AUTOSAR XML (schema 4-0-3)
standard types defined: Boolean, UInt16, UInt32
package /AUTOSAR_Platform/DataConstrs
  range DC_Boolean: raw 0..1
  range DC_UInt16: raw 0..65535
package /PATAC/MSM/ComponentTypes
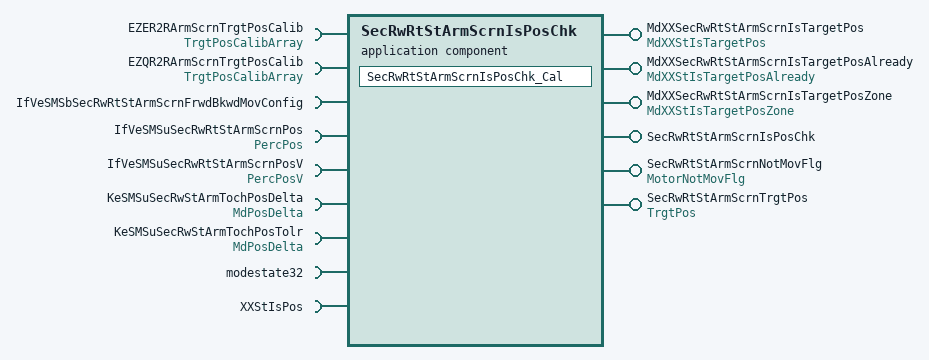
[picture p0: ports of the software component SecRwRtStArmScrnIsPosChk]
  application sw component type SecRwRtStArmScrnIsPosChk
    6 x provide port:
      MdXXSecRwRtStArmScrnIsTargetPos: nonqueued-sender-com-spec=data-element=MdXXStIsTargetPos/Val, provided-interface=MdXXStIsTargetPos
      MdXXSecRwRtStArmScrnIsTargetPosAlready: nonqueued-sender-com-spec=data-element=MdXXStIsTargetPosAlready/Val, provided-interface=MdXXStIsTargetPosAlready
      MdXXSecRwRtStArmScrnIsTargetPosZone: nonqueued-sender-com-spec=data-element=MdXXStIsTargetPosZone/Val, provided-interface=MdXXStIsTargetPosZone
      SecRwRtStArmScrnIsPosChk: server-com-spec{operation=Cal, queue-length=1}, provided-interface=SecRwRtStArmScrnIsPosChk
      SecRwRtStArmScrnNotMovFlg: nonqueued-sender-com-spec{data-element=MotorNotMovFlg/Val, init-value=0}, provided-interface=MotorNotMovFlg
      SecRwRtStArmScrnTrgtPos: nonqueued-sender-com-spec{data-element=TrgtPos/Val, init-value=4095}, provided-interface=TrgtPos
    9 x require port:
      EZER2RArmScrnTrgtPosCalib: nonqueued-receiver-com-spec{data-element=TrgtPosArray, filter=data-filter-type=ALWAYS, init-value=[4095, 4095, 4095]}, required-interface=TrgtPosCalibArray
      EZQR2RArmScrnTrgtPosCalib: nonqueued-receiver-com-spec{data-element=TrgtPosArray, filter=data-filter-type=ALWAYS, init-value=[4095, 4095, 4095]}, required-interface=TrgtPosCalibArray
      IfVeSMSbSecRwRtStArmScrnFrwdBkwdMovConfig: nonqueued-receiver-com-spec{data-element=IfVeSMSbSecRwRtStArmScrnFrwdBkwdMovConfig/Val, filter=data-filter-type=ALWAYS, init-value=0}, required-interface=IfVeSMSbSecRwRtStArmScrnFrwdBkwdMovConfig
      IfVeSMSuSecRwRtStArmScrnPos: nonqueued-receiver-com-spec{data-element=PercPos/Val, filter=data-filter-type=ALWAYS, init-value=0}, required-interface=PercPos
      IfVeSMSuSecRwRtStArmScrnPosV: nonqueued-receiver-com-spec{data-element=PercPosV/Val, filter=data-filter-type=ALWAYS, init-value=0}, required-interface=PercPosV
      KeSMSuSecRwStArmTochPosDelta: parameter-require-com-spec{init-value=150, parameter=Val}, required-interface=MdPosDelta
      KeSMSuSecRwStArmTochPosTolr: parameter-require-com-spec{init-value=150, parameter=Val}, required-interface=MdPosDelta
      modestate32: nonqueued-receiver-com-spec{data-element=modestate32/Val, filter=data-filter-type=ALWAYS, init-value=0}, required-interface=modestate32
      XXStIsPos: client-com-spec=Get, required-interface=XXStIsPos
    behavior SecRwRtStArmScrnIsPosChk_InternalBehavior
      operation invoked event OIT_SecRwRtStArmScrnIsPosChk_Cal_SecRwRtStArmScrnIsPosChk_Cal: start-on-event=SecRwRtStArmScrnIsPosChk_Cal, operation=SecRwRtStArmScrnIsPosChk.Cal
      runnable SecRwRtStArmScrnIsPosChk_Cal
        data-receive-point-by-arguments:
          6 x access:
            REC_EZER2RArmScrnTrgtPosCalib_TrgtPosArray: accessed-variable=EZER2RArmScrnTrgtPosCalib.TrgtPosArray
            REC_EZQR2RArmScrnTrgtPosCalib_TrgtPosArray: accessed-variable=EZQR2RArmScrnTrgtPosCalib.TrgtPosArray
            REC_IfVeSMSbSecRwRtStArmScrnFrwdBkwdMovConfig_Val: accessed-variable=IfVeSMSbSecRwRtStArmScrnFrwdBkwdMovConfig.Val
            REC_IfVeSMSuSecRwRtStArmScrnPos_Val: accessed-variable=IfVeSMSuSecRwRtStArmScrnPos.Val
            REC_IfVeSMSuSecRwRtStArmScrnPosV_Val: accessed-variable=IfVeSMSuSecRwRtStArmScrnPosV.Val
            REC_modestate32_Val: accessed-variable=modestate32.Val
        data-send-points:
          5 x access:
            SEND_MdXXSecRwRtStArmScrnIsTargetPos_Val: accessed-variable=MdXXSecRwRtStArmScrnIsTargetPos.Val
            SEND_MdXXSecRwRtStArmScrnIsTargetPosAlready_Val: accessed-variable=MdXXSecRwRtStArmScrnIsTargetPosAlready.Val
            SEND_MdXXSecRwRtStArmScrnIsTargetPosZone_Val: accessed-variable=MdXXSecRwRtStArmScrnIsTargetPosZone.Val
            SEND_SecRwRtStArmScrnNotMovFlg_Val: accessed-variable=SecRwRtStArmScrnNotMovFlg.Val
            SEND_SecRwRtStArmScrnTrgtPos_Val: accessed-variable=SecRwRtStArmScrnTrgtPos.Val
        parameter access PA_KeSMSuSecRwStArmTochPosDelta_Val: accessed-parameter=KeSMSuSecRwStArmTochPosDelta.Val
        parameter access PA_KeSMSuSecRwStArmTochPosTolr_Val: accessed-parameter=KeSMSuSecRwStArmTochPosTolr.Val
        sync call SC_XXStIsPos_Get: operation=XXStIsPos.Get, timeout=0
  swc implementation SecRwRtStArmScrnIsPosChk_Implementation: behavior=SecRwRtStArmScrnIsPosChk_InternalBehavior
    code-descriptors:
      code Default: artifact-descriptors=autosar-engineering-object={short-label=Default, category=SWSRC}
package /PATAC/MSM/ModeAdjust/CalPortInterface
  parameter interface MdPosDelta
    parameter data prototype Val: sw-calibration-access=READ-WRITE, type=UInt16
package /PATAC/MSM/ModeAdjust/DataType
  impl type TrgtPosCalibArray: category=ARRAY, sw-calibration-access=READ-ONLY, type-emitter=RTE  # 0:pos 1:max 2:min
    element Element: array-size=3, array-size-semantics=FIXED-SIZE, implementation-data-type=UInt16, invalid-value=0
package /PATAC/MSM/ModeAdjust/PortInterface
  client server interface SecRwRtStArmScrnIsPosChk
    operation Cal
  client server interface XXStIsPos
    operation Get
      8 x arg, all with server-argument-impl-policy=USE-ARGUMENT-TYPE:
        PosV: type=DataTypes/Boolean, direction=IN
        Pos: type=UInt16, direction=IN
        CalibArray: type=TrgtPosCalibArray, direction=IN
        Delta: type=UInt16, direction=IN
        Tolr: type=UInt16, direction=IN
        IsPos: type=DataTypes/Boolean, direction=OUT
        IsPosZone: type=DataTypes/Boolean, direction=OUT
        IsPosAlready: type=DataTypes/Boolean, direction=OUT
  9 x sender receiver interface:
    IfVeSMSbSecRwRtStArmScrnFrwdBkwdMovConfig: invalidation-policy{data-element=IfVeSMSbSecRwRtStArmScrnFrwdBkwdMovConfig/Val, handle-invalid=DONT-INVALIDATE}
      data Val: type=Implementation/Boolean
    MdXXStIsTargetPos: invalidation-policy{data-element=MdXXStIsTargetPos/Val, handle-invalid=DONT-INVALIDATE}
      data Val: type=UInt32
    MdXXStIsTargetPosAlready: invalidation-policy{data-element=MdXXStIsTargetPosAlready/Val, handle-invalid=DONT-INVALIDATE}
      data Val: type=UInt32
    MdXXStIsTargetPosZone: invalidation-policy{data-element=MdXXStIsTargetPosZone/Val, handle-invalid=DONT-INVALIDATE}
      data Val: type=UInt32
    modestate32: invalidation-policy{data-element=modestate32/Val, handle-invalid=DONT-INVALIDATE}
      data Val: type=UInt32
    MotorNotMovFlg: invalidation-policy{data-element=MotorNotMovFlg/Val, handle-invalid=DONT-INVALIDATE}
      data Val: type=Implementation/Boolean
    PercPos: invalidation-policy{data-element=PercPos/Val, handle-invalid=DONT-INVALIDATE}
      data Val: type=UInt16
    PercPosV: invalidation-policy{data-element=PercPosV/Val, handle-invalid=DONT-INVALIDATE}
      data Val: type=Implementation/Boolean
    TrgtPosCalibArray: invalidation-policy{data-element=TrgtPosArray, handle-invalid=DONT-INVALIDATE}
      data TrgtPosArray: type=TrgtPosCalibArray  # 0:Pos 1:Max 2:Min
package /PATAC/MSM/PortInterfaces
  sender receiver interface TrgtPos: invalidation-policy{data-element=TrgtPos/Val, handle-invalid=DONT-INVALIDATE}
    data Val: type=UInt16
